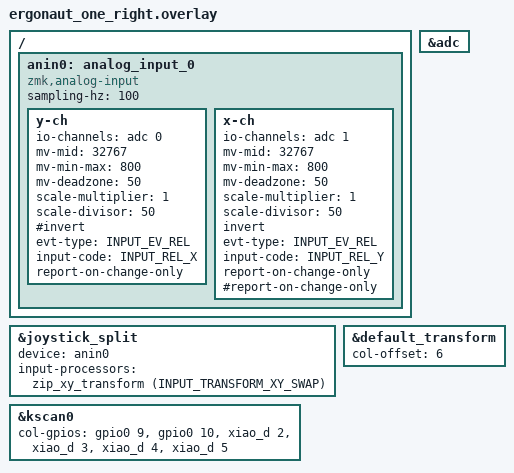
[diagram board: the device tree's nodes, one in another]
/*
 * Copyright (c) 2020 The ZMK Contributors
 *
 * SPDX-License-Identifier: MIT
 */

#include "ergonaut_one.dtsi"
#include <zephyr/dt-bindings/input/input-event-codes.h>
#include <input/processors.dtsi>
#include <dt-bindings/zmk/input_transform.h>
#include <dt-bindings/zmk/keys.h>

// 校准相关常量定义
#define ANALOG_INPUT_AUTO_CALIBRATE_FLAG 32767  // 0x7FFF
#define ANALOG_INPUT_STABILIZE_DELAY_MS 50      // 校准前稳定时间(ms)
#define ANALOG_INPUT_CALIBRATE_SAMPLES 5        // 每次校准采样次数
#define ANALOG_INPUT_CALIBRATE_MAX_RETRIES 2    // 最大校准重试次数
#define ANALOG_INPUT_CALIBRATE_VARIANCE_THRESHOLD 50  // 最大允许方差(mV)

&adc {
	status = "okay";
};

/ {
	anin0: analog_input_0 {
		compatible = "zmk,analog-input";
		sampling-hz = <100>;
		y-ch {
			io-channels = <&adc 0>; // <--- see ain-map.png for nRF52840
      // Set to 32767 (0x7FFF) to enable auto-calibration
			mv-mid = <32767>; // Y軸のニュートラル（中央）でのミリボルト値
			mv-min-max = <800>;
			mv-deadzone = <50>;
			scale-multiplier = <1>;
			scale-divisor = <50>;
			#invert;
			evt-type = <INPUT_EV_REL>;
			input-code = <INPUT_REL_X>;
			report-on-change-only;
		};
		x-ch {
			io-channels = <&adc 1>; // <--- see ain-map.png for nRF52840
			// Set to 32767 (0x7FFF) to enable auto-calibration
			mv-mid = <32767>; // Y軸のニュートラル（中央）でのミリボルト値
			mv-min-max = <800>;
			mv-deadzone = <50>;
			scale-multiplier = <1>;
			scale-divisor = <50>;
			invert;
			evt-type = <INPUT_EV_REL>;
			input-code = <INPUT_REL_Y>;
			report-on-change-only;

			/* enable report mdoe for gamepad axix or knob */
			/* to only call input_report on quantquantized value is updated */
			/* NOTE: mouse input does NOT need this */
			#report-on-change-only;

		};
	};
	
};

&joystick_split {
	device = <&anin0>;
	input-processors = <&zip_xy_transform (INPUT_TRANSFORM_XY_SWAP)>;
};

&default_transform {
    col-offset = <6>;
};

&kscan0 {
    col-gpios
        = <&gpio0 9 GPIO_ACTIVE_HIGH>
        , <&gpio0 10 GPIO_ACTIVE_HIGH>
        , <&xiao_d 2 GPIO_ACTIVE_HIGH>
        , <&xiao_d 3 GPIO_ACTIVE_HIGH>
        , <&xiao_d 4 GPIO_ACTIVE_HIGH>
        , <&xiao_d 5 GPIO_ACTIVE_HIGH>
        ;
};
